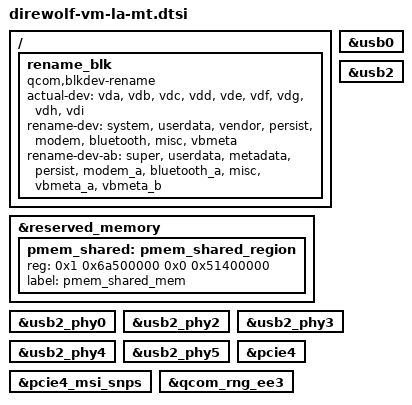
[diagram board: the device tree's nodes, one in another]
&reserved_memory {
	pmem_shared: pmem_shared_region {
		reg = <0x1 0x6a500000 0x0 0x51400000>;
		label = "pmem_shared_mem";
	};
};

#include "display/quin-vm-display-la.dtsi"
#include "direwolf-cnss.dtsi"

/ {
	rename_blk: rename_blk {
		compatible = "qcom,blkdev-rename";
		actual-dev = "vda", "vdb", "vdc",
				"vdd", "vde", "vdf",
				"vdg", "vdh", "vdi";
		rename-dev = "system", "userdata", "vendor",
				"persist", "modem", "bluetooth",
				"misc", "vbmeta";
		rename-dev-ab = "super", "userdata", "metadata",
				"persist", "modem_a", "bluetooth_a",
				"misc", "vbmeta_a", "vbmeta_b";
	};
};

&usb0 {
	status = "okay";
};

&usb2_phy0 {
	status = "okay";
};

&usb2 {
	status = "okay";
};

&usb2_phy2 {
	status = "okay";
};

&usb2_phy3 {
	status = "okay";
};

&usb2_phy4 {
	status = "okay";
};

&usb2_phy5 {
	status = "okay";
};

&pcie4 {
	status = "okay";
};

&pcie4_msi_snps {
	status = "okay";
};

&qcom_rng_ee3 {
	status = "okay";
};

#include "direwolf-vm-gnss.dtsi"
